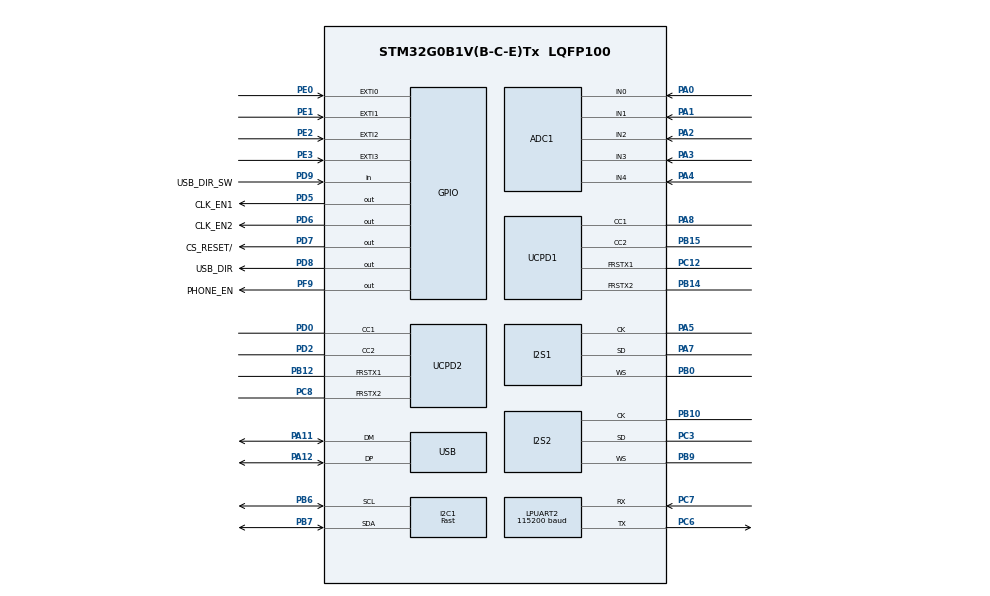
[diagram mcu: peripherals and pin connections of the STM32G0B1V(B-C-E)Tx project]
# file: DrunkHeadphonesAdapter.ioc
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ADC1.Channel-0\#ChannelRegularConversion=ADC_CHANNEL_1
ADC1.Channel-1\#ChannelRegularConversion=ADC_CHANNEL_3
ADC1.Channel-2\#ChannelRegularConversion=ADC_CHANNEL_0
ADC1.Channel-3\#ChannelRegularConversion=ADC_CHANNEL_2
ADC1.Channel-4\#ChannelRegularConversion=ADC_CHANNEL_4
ADC1.Channel-5\#ChannelRegularConversion=ADC_CHANNEL_VREFINT
ADC1.Channel-6\#ChannelRegularConversion=ADC_CHANNEL_TEMPSENSOR
ADC1.ContinuousConvMode=ENABLE
ADC1.DMAContinuousRequests=ENABLE
ADC1.EOCSelection=ADC_EOC_SEQ_CONV
ADC1.EnableAnalogWatchDog1=false
ADC1.EnableAnalogWatchDog2=false
ADC1.NbrOfConversion=7
ADC1.NbrOfConversionFlag=1
ADC1.Overrun=ADC_OVR_DATA_OVERWRITTEN
ADC1.Rank-0\#ChannelRegularConversion=1
ADC1.Rank-1\#ChannelRegularConversion=2
ADC1.Rank-2\#ChannelRegularConversion=3
ADC1.Rank-3\#ChannelRegularConversion=4
ADC1.Rank-4\#ChannelRegularConversion=5
ADC1.Rank-5\#ChannelRegularConversion=6
ADC1.Rank-6\#ChannelRegularConversion=7
ADC1.SamplingTime-0\#ChannelRegularConversion=ADC_SAMPLINGTIME_COMMON_1
ADC1.SamplingTime-1\#ChannelRegularConversion=ADC_SAMPLINGTIME_COMMON_1
ADC1.SamplingTime-2\#ChannelRegularConversion=ADC_SAMPLINGTIME_COMMON_1
ADC1.SamplingTime-3\#ChannelRegularConversion=ADC_SAMPLINGTIME_COMMON_1
ADC1.SamplingTime-4\#ChannelRegularConversion=ADC_SAMPLINGTIME_COMMON_1
ADC1.SamplingTime-5\#ChannelRegularConversion=ADC_SAMPLINGTIME_COMMON_2
ADC1.SamplingTime-6\#ChannelRegularConversion=ADC_SAMPLINGTIME_COMMON_2
ADC1.SamplingTimeCommon1=ADC_SAMPLETIME_39CYCLES_5
ADC1.SamplingTimeCommon2=ADC_SAMPLETIME_160CYCLES_5
ADC1.SelectedChannel=ADC_CHANNEL_0|ADC_CHANNEL_1|ADC_CHANNEL_2|ADC_CHANNEL_3|ADC_CHANNEL_4|ADC_CHANNEL_TEMPSENSOR|ADC_CHANNEL_VREFINT
ADC1.master=1
Dma.ADC1.4.Direction=DMA_PERIPH_TO_MEMORY
Dma.ADC1.4.EventEnable=DISABLE
Dma.ADC1.4.Instance=DMA1_Channel5
Dma.ADC1.4.MemDataAlignment=DMA_MDATAALIGN_HALFWORD
Dma.ADC1.4.MemInc=DMA_MINC_ENABLE
Dma.ADC1.4.Mode=DMA_CIRCULAR
Dma.ADC1.4.PeriphDataAlignment=DMA_PDATAALIGN_HALFWORD
Dma.ADC1.4.PeriphInc=DMA_PINC_DISABLE
Dma.ADC1.4.Polarity=HAL_DMAMUX_REQ_GEN_RISING
Dma.ADC1.4.Priority=DMA_PRIORITY_LOW
Dma.ADC1.4.RequestNumber=1
Dma.ADC1.4.SignalID=NONE
Dma.ADC1.4.SyncEnable=DISABLE
Dma.ADC1.4.SyncPolarity=HAL_DMAMUX_SYNC_NO_EVENT
Dma.ADC1.4.SyncRequestNumber=1
Dma.ADC1.4.SyncSignalID=NONE
Dma.Request0=UCPD1_RX
Dma.Request1=UCPD1_TX
Dma.Request2=UCPD2_RX
Dma.Request3=UCPD2_TX
Dma.Request4=ADC1
Dma.UCPD1_RX.0.Direction=DMA_PERIPH_TO_MEMORY
Dma.UCPD1_RX.0.EventEnable=DISABLE
Dma.UCPD1_RX.0.Instance=DMA1_Channel1
Dma.UCPD1_RX.0.MemDataAlignment=DMA_MDATAALIGN_BYTE
Dma.UCPD1_RX.0.MemInc=DMA_MINC_ENABLE
Dma.UCPD1_RX.0.Mode=DMA_NORMAL
Dma.UCPD1_RX.0.PeriphDataAlignment=DMA_PDATAALIGN_BYTE
Dma.UCPD1_RX.0.PeriphInc=DMA_PINC_DISABLE
Dma.UCPD1_RX.0.Polarity=HAL_DMAMUX_REQ_GEN_RISING
Dma.UCPD1_RX.0.Priority=DMA_PRIORITY_LOW
Dma.UCPD1_RX.0.RequestNumber=1
Dma.UCPD1_RX.0.SignalID=NONE
Dma.UCPD1_RX.0.SyncEnable=DISABLE
Dma.UCPD1_RX.0.SyncPolarity=HAL_DMAMUX_SYNC_NO_EVENT
Dma.UCPD1_RX.0.SyncRequestNumber=1
Dma.UCPD1_RX.0.SyncSignalID=NONE
Dma.UCPD1_TX.1.Direction=DMA_MEMORY_TO_PERIPH
Dma.UCPD1_TX.1.EventEnable=DISABLE
Dma.UCPD1_TX.1.Instance=DMA1_Channel2
Dma.UCPD1_TX.1.MemDataAlignment=DMA_MDATAALIGN_BYTE
Dma.UCPD1_TX.1.MemInc=DMA_MINC_ENABLE
Dma.UCPD1_TX.1.Mode=DMA_NORMAL
Dma.UCPD1_TX.1.PeriphDataAlignment=DMA_PDATAALIGN_BYTE
Dma.UCPD1_TX.1.PeriphInc=DMA_PINC_DISABLE
Dma.UCPD1_TX.1.Polarity=HAL_DMAMUX_REQ_GEN_RISING
Dma.UCPD1_TX.1.Priority=DMA_PRIORITY_LOW
Dma.UCPD1_TX.1.RequestNumber=1
Dma.UCPD1_TX.1.SignalID=NONE
Dma.UCPD1_TX.1.SyncEnable=DISABLE
Dma.UCPD1_TX.1.SyncPolarity=HAL_DMAMUX_SYNC_NO_EVENT
Dma.UCPD1_TX.1.SyncRequestNumber=1
Dma.UCPD1_TX.1.SyncSignalID=NONE
Dma.UCPD2_RX.2.Direction=DMA_PERIPH_TO_MEMORY
Dma.UCPD2_RX.2.EventEnable=DISABLE
Dma.UCPD2_RX.2.Instance=DMA1_Channel3
Dma.UCPD2_RX.2.MemDataAlignment=DMA_MDATAALIGN_BYTE
Dma.UCPD2_RX.2.MemInc=DMA_MINC_ENABLE
Dma.UCPD2_RX.2.Mode=DMA_NORMAL
Dma.UCPD2_RX.2.PeriphDataAlignment=DMA_PDATAALIGN_BYTE
Dma.UCPD2_RX.2.PeriphInc=DMA_PINC_DISABLE
Dma.UCPD2_RX.2.Polarity=HAL_DMAMUX_REQ_GEN_RISING
Dma.UCPD2_RX.2.Priority=DMA_PRIORITY_LOW
Dma.UCPD2_RX.2.RequestNumber=1
Dma.UCPD2_RX.2.SignalID=NONE
Dma.UCPD2_RX.2.SyncEnable=DISABLE
Dma.UCPD2_RX.2.SyncPolarity=HAL_DMAMUX_SYNC_NO_EVENT
Dma.UCPD2_RX.2.SyncRequestNumber=1
Dma.UCPD2_RX.2.SyncSignalID=NONE
Dma.UCPD2_TX.3.Direction=DMA_MEMORY_TO_PERIPH
Dma.UCPD2_TX.3.EventEnable=DISABLE
Dma.UCPD2_TX.3.Instance=DMA1_Channel4
Dma.UCPD2_TX.3.MemDataAlignment=DMA_MDATAALIGN_BYTE
Dma.UCPD2_TX.3.MemInc=DMA_MINC_ENABLE
Dma.UCPD2_TX.3.Mode=DMA_NORMAL
Dma.UCPD2_TX.3.PeriphDataAlignment=DMA_PDATAALIGN_BYTE
Dma.UCPD2_TX.3.PeriphInc=DMA_PINC_DISABLE
Dma.UCPD2_TX.3.Polarity=HAL_DMAMUX_REQ_GEN_RISING
Dma.UCPD2_TX.3.Priority=DMA_PRIORITY_LOW
Dma.UCPD2_TX.3.RequestNumber=1
Dma.UCPD2_TX.3.SignalID=NONE
Dma.UCPD2_TX.3.SyncEnable=DISABLE
Dma.UCPD2_TX.3.SyncPolarity=HAL_DMAMUX_SYNC_NO_EVENT
Dma.UCPD2_TX.3.SyncRequestNumber=1
Dma.UCPD2_TX.3.SyncSignalID=NONE
FREERTOS.Tasks01=defaultTask,24,128,StartDefaultTask,Default,NULL,Dynamic,NULL,NULL
FREERTOS.configTOTAL_HEAP_SIZE=32768
FREERTOS.configUSE_TICKLESS_IDLE=1
I2C1.I2C_Rise_Time=300
I2C1.I2C_Speed_Mode=I2C_Fast
I2C1.Timing=0x00600614
I2S1.AudioFreq=I2S_AUDIOFREQ_96K
I2S1.DataFormat=I2S_DATAFORMAT_32B
I2S1.ErrorAudioFreq=4.16 %
I2S1.FullDuplexMode=I2S_FULLDUPLEXMODE_DISABLE
I2S1.Instance=SPI$Index
I2S1.RealAudioFreq=100.0 KHz
I2S1.VirtualMode=I2S_MODE_SLAVE
I2S2.AudioFreq=I2S_AUDIOFREQ_96K
I2S2.DataFormat=I2S_DATAFORMAT_24B
I2S2.ErrorAudioFreq=4.16 %
I2S2.FullDuplexMode=I2S_FULLDUPLEXMODE_DISABLE
I2S2.Instance=SPI$Index
I2S2.RealAudioFreq=100.0 KHz
I2S2.VirtualMode=I2S_MODE_SLAVE
LPUART2.BaudRate=115200
LPUART2.WordLength=UART_WORDLENGTH_8B
Mcu.Family=STM32G0
Mcu.Name=STM32G0B1V(B-C-E)Tx
Mcu.Package=LQFP100
NVIC.ADC1_COMP_IRQn=true\:3\:0\:false\:false\:true\:true\:true\:true\:true
NVIC.DMA1_Ch4_7_DMA2_Ch1_5_DMAMUX1_OVR_IRQn=true\:3\:0\:false\:false\:true\:true\:false\:true\:true
NVIC.DMA1_Channel1_IRQn=true\:3\:0\:false\:false\:true\:true\:false\:true\:true
NVIC.DMA1_Channel2_3_IRQn=true\:3\:0\:false\:false\:true\:true\:false\:true\:true
NVIC.EXTI0_1_IRQn=true\:3\:0\:false\:false\:true\:true\:true\:true\:true
NVIC.EXTI2_3_IRQn=true\:3\:0\:false\:false\:true\:true\:true\:true\:true
NVIC.TIM6_DAC_LPTIM1_IRQn=true\:3\:0\:false\:false\:true\:false\:false\:true\:true
NVIC.TimeBase=TIM6_DAC_LPTIM1_IRQn
NVIC.TimeBaseIP=TIM6
NVIC.USB_UCPD1_2_IRQn=true\:3\:0\:true\:false\:true\:true\:true\:true\:true
PA0.Mode=IN0
PA0.Signal=ADC1_IN0
PA1.Mode=IN1
PA1.Signal=ADC1_IN1
PA11\ [PA9].Mode=Device
PA11\ [PA9].Signal=USB_DM
PA12\ [PA10].Mode=Device
PA12\ [PA10].Signal=USB_DP
PA13.Mode=Serial_Wire
PA13.Signal=SYS_SWDIO
PA14-BOOT0.Mode=Serial_Wire
PA14-BOOT0.Signal=SYS_SWCLK
PA2.Mode=IN2
PA2.Signal=ADC1_IN2
PA3.Mode=IN3
PA3.Signal=ADC1_IN3
PA4.Mode=IN4
PA4.Signal=ADC1_IN4
PA5.Mode=Half_Duplex_Slave
PA5.Signal=I2S1_CK
PA7.Mode=Half_Duplex_Slave
PA7.Signal=I2S1_SD
PA8.Mode=Dual_Role_AllSignals
PA8.Signal=UCPD1_CC1
PB0.Mode=Half_Duplex_Slave
PB0.Signal=I2S1_WS
PB10.Mode=Half_Duplex_Slave
PB10.Signal=I2S2_CK
PB12.Mode=FRSTX_CC2
PB12.Signal=UCPD2_FRSTX1
PB14.Mode=FRSTX_CC2
PB14.Signal=UCPD1_FRSTX2
PB15.Mode=Dual_Role_AllSignals
PB15.Signal=UCPD1_CC2
PB6.Mode=I2C
PB6.Signal=I2C1_SCL
PB7.Mode=I2C
PB7.Signal=I2C1_SDA
PB9.Mode=Half_Duplex_Slave
PB9.Signal=I2S2_WS
PC12.Mode=FRSTX_CC2
PC12.Signal=UCPD1_FRSTX1
PC3.Mode=Half_Duplex_Slave
PC3.Signal=I2S2_SD
PC6.Mode=Asynchronous
PC6.Signal=LPUART2_TX
PC7.Mode=Asynchronous
PC7.Signal=LPUART2_RX
PC8.Mode=FRSTX_CC2
PC8.Signal=UCPD2_FRSTX2
PD0.Mode=Dual_Role_AllSignals
PD0.Signal=UCPD2_CC1
PD2.Mode=Dual_Role_AllSignals
PD2.Signal=UCPD2_CC2
PD5.GPIO_Label=CLK_EN1
PD5.Signal=GPIO_Output
PD6.GPIO_Label=CLK_EN2
PD6.Signal=GPIO_Output
PD7.GPIO_Label=CS_RESET/
PD7.Signal=GPIO_Output
PD8.GPIO_Label=USB_DIR
PD8.Signal=GPIO_Output
PD9.GPIO_Label=USB_DIR_SW
PD9.Signal=GPIO_Input
PE0.GPIO_ModeDefaultEXTI=GPIO_MODE_IT_FALLING
PE0.Signal=GPXTI0
PE1.GPIO_ModeDefaultEXTI=GPIO_MODE_IT_FALLING
PE1.Signal=GPXTI1
PE2.GPIO_ModeDefaultEXTI=GPIO_MODE_IT_FALLING
PE2.Signal=GPXTI2
PE3.GPIO_ModeDefaultEXTI=GPIO_MODE_IT_FALLING
PE3.Signal=GPXTI3
PF9.GPIO_Label=PHONE_EN
PF9.Signal=GPIO_Output
ProjectManager.HeapSize=0x200
ProjectManager.StackSize=0x400
ProjectManager.TargetToolchain=Makefile
RCC.ADCFreq_Value=64000000
RCC.AHBFreq_Value=64000000
RCC.APB1CLKDivider=RCC_HCLK_DIV4
RCC.CortexFreq_Value=64000000
RCC.EXTERNAL_CLOCK_VALUE=48000
RCC.HCLKFreq_Value=64000000
RCC.HSE_VALUE=16000000
RCC.HSI48_VALUE=48000000
RCC.HSI_VALUE=16000000
RCC.LSE_VALUE=32768
RCC.SYSCLKFreq_VALUE=64000000
RCC.SYSCLKSource=RCC_SYSCLKSOURCE_PLLCLK
RCC.USBFreq_Value=48000000
RCC.VCOOutputFreq_Value=128000000
STMicroelectronics.X-CUBE-TCPP.4.2.0.tcpp0203CcBoardOoPartJjtcpp0203Jjtcpp0203=true
VP_ADC1_TempSens_Input.Mode=IN-TempSens
VP_ADC1_Vref_Input.Mode=IN-Vrefint
VP_FREERTOS_VS_CMSIS_V2.Mode=CMSIS_V2
VP_RCC_USB.Mode=CRS SYNC Source USB
VP_STMicroelectronics.X-CUBE-TCPP_VS_BoardOoPartJjtcpp0203_1.2.3_4.2.0.Mode=BoardOoPartJjtcpp0203
VP_SYS_VS_DBSignals.Mode=DisableDeadBatterySignals
VP_SYS_VS_tim6.Mode=TIM6
VP_USBPD_VS_PD3FULL.Mode=PD3_Full_Stack
VP_USBPD_VS_USBPD12.Mode=USBPD_P0P1
VP_USBPD_VS_usbpd_tim1.Mode=TIM1
board=custom

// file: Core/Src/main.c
/* USER CODE BEGIN Header */
/**
  ******************************************************************************
  * @file           : main.c
  * @brief          : Main program body
  ******************************************************************************
  * @attention
  *
  * Copyright (c) 2026 STMicroelectronics.
  * All rights reserved.
  *
  * This software is licensed under terms that can be found in the LICENSE file
  * in the root directory of this software component.
  * If no LICENSE file comes with this software, it is provided AS-IS.
  *
  ******************************************************************************
  */
/* USER CODE END Header */
#include "main.h"
#include "cmsis_os.h"
#include "usbpd.h"

/* USER CODE BEGIN Includes */
#include "app_main.h"

/* USER CODE END Includes */

PCD_HandleTypeDef hpcd_USB_DRD_FS;

/* Definitions for defaultTask */
osThreadId_t defaultTaskHandle;
const osThreadAttr_t defaultTask_attributes = {
  .name = "defaultTask",
  .priority = (osPriority_t) osPriorityNormal,
  .stack_size = 128 * 4
};

void SystemClock_Config(void);
static void MX_GPIO_Init(void);
static void MX_DMA_Init(void);
static void MX_I2S1_Init(void);
static void MX_I2S2_Init(void);
static void MX_UCPD1_Init(void);
static void MX_UCPD2_Init(void);
static void MX_I2C1_Init(void);
static void MX_ADC1_Init(void);
static void MX_LPUART2_UART_Init(void);
static void MX_USB_DRD_FS_PCD_Init(void);
void StartDefaultTask(void *argument);

int main(void)
{

  /* MCU Configuration--------------------------------------------------------*/

  /* Reset of all peripherals, Initializes the Flash interface and the Systick. */
  HAL_Init();

  /* Configure the system clock */
  SystemClock_Config();

  /* Initialize all configured peripherals */
  MX_GPIO_Init();
  MX_DMA_Init();
  MX_I2S1_Init();
  MX_I2S2_Init();
  MX_UCPD1_Init();
  MX_UCPD2_Init();
  MX_I2C1_Init();
  MX_ADC1_Init();
  MX_LPUART2_UART_Init();

  /* Init scheduler */
  osKernelInitialize();
  /* USBPD initialisation ---------------------------------*/
  MX_USBPD_Init();

  /* Create the thread(s) */
  /* creation of defaultTask */
  defaultTaskHandle = osThreadNew(StartDefaultTask, NULL, &defaultTask_attributes);

  /* Start scheduler */
  osKernelStart();

  /* We should never get here as control is now taken by the scheduler */

  /* Infinite loop */
  /* USER CODE BEGIN WHILE */
  app_main();
  while (1)
  {
    /* USER CODE END WHILE */

  }
}

void SystemClock_Config(void)
{
  LL_FLASH_SetLatency(LL_FLASH_LATENCY_2);
  while(LL_FLASH_GetLatency() != LL_FLASH_LATENCY_2)
  {
  }

  /* HSI configuration and activation */
  LL_RCC_HSI_Enable();
  while(LL_RCC_HSI_IsReady() != 1)
  {
  }

  LL_RCC_HSI48_Enable();

   /* Wait till HSI48 is ready */
  while(LL_RCC_HSI48_IsReady() != 1)
  {
  }

  /* Main PLL configuration and activation */
  LL_RCC_PLL_ConfigDomain_SYS(LL_RCC_PLLSOURCE_HSI, LL_RCC_PLLM_DIV_1, 8, LL_RCC_PLLR_DIV_2);
  LL_RCC_PLL_Enable();
  LL_RCC_PLL_EnableDomain_SYS();
  while(LL_RCC_PLL_IsReady() != 1)
  {
  }

  /* Set AHB prescaler*/
  LL_RCC_SetAHBPrescaler(LL_RCC_SYSCLK_DIV_1);

  /* Sysclk activation on the main PLL */
  LL_RCC_SetSysClkSource(LL_RCC_SYS_CLKSOURCE_PLL);
  while(LL_RCC_GetSysClkSource() != LL_RCC_SYS_CLKSOURCE_STATUS_PLL)
  {
  }

  /* Set APB1 prescaler*/
  LL_RCC_SetAPB1Prescaler(LL_RCC_APB1_DIV_4);
  /* Update CMSIS variable (which can be updated also through SystemCoreClockUpdate function) */
  LL_SetSystemCoreClock(64000000);

   /* Update the time base */
  if (HAL_InitTick (TICK_INT_PRIORITY) != HAL_OK)
  {
    Error_Handler();
  }
  LL_APB1_GRP1_EnableClock(LL_APB1_GRP1_PERIPH_CRS);
  LL_APB1_GRP1_ForceReset(LL_APB1_GRP1_PERIPH_CRS);
  LL_APB1_GRP1_ReleaseReset(LL_APB1_GRP1_PERIPH_CRS);
  LL_CRS_SetSyncDivider(LL_CRS_SYNC_DIV_1);
  LL_CRS_SetSyncPolarity(LL_CRS_SYNC_POLARITY_RISING);
  LL_CRS_SetSyncSignalSource(LL_CRS_SYNC_SOURCE_USB);
  LL_CRS_SetReloadCounter(__LL_CRS_CALC_CALCULATE_RELOADVALUE(48000000,1000));
  LL_CRS_SetFreqErrorLimit(34);
  LL_CRS_SetHSI48SmoothTrimming(32);
}

static void MX_ADC1_Init(void)
{

  LL_ADC_InitTypeDef ADC_InitStruct = {0};
  LL_ADC_REG_InitTypeDef ADC_REG_InitStruct = {0};

  LL_GPIO_InitTypeDef GPIO_InitStruct = {0};

  /* Peripheral clock enable */
  LL_APB2_GRP1_EnableClock(LL_APB2_GRP1_PERIPH_ADC);

  LL_IOP_GRP1_EnableClock(LL_IOP_GRP1_PERIPH_GPIOA);
  /**ADC1 GPIO Configuration
  PA0   ------> ADC1_IN0
  PA1   ------> ADC1_IN1
  PA2   ------> ADC1_IN2
  PA3   ------> ADC1_IN3
  PA4   ------> ADC1_IN4
  */
  GPIO_InitStruct.Pin = LL_GPIO_PIN_0;
  GPIO_InitStruct.Mode = LL_GPIO_MODE_ANALOG;
  GPIO_InitStruct.Pull = LL_GPIO_PULL_NO;
  LL_GPIO_Init(GPIOA, &GPIO_InitStruct);

  GPIO_InitStruct.Pin = LL_GPIO_PIN_1;
  GPIO_InitStruct.Mode = LL_GPIO_MODE_ANALOG;
  GPIO_InitStruct.Pull = LL_GPIO_PULL_NO;
  LL_GPIO_Init(GPIOA, &GPIO_InitStruct);

  GPIO_InitStruct.Pin = LL_GPIO_PIN_2;
  GPIO_InitStruct.Mode = LL_GPIO_MODE_ANALOG;
  GPIO_InitStruct.Pull = LL_GPIO_PULL_NO;
  LL_GPIO_Init(GPIOA, &GPIO_InitStruct);

  GPIO_InitStruct.Pin = LL_GPIO_PIN_3;
  GPIO_InitStruct.Mode = LL_GPIO_MODE_ANALOG;
  GPIO_InitStruct.Pull = LL_GPIO_PULL_NO;
  LL_GPIO_Init(GPIOA, &GPIO_InitStruct);

  GPIO_InitStruct.Pin = LL_GPIO_PIN_4;
  GPIO_InitStruct.Mode = LL_GPIO_MODE_ANALOG;
  GPIO_InitStruct.Pull = LL_GPIO_PULL_NO;
  LL_GPIO_Init(GPIOA, &GPIO_InitStruct);

  /* ADC1 DMA Init */

  /* ADC1 Init */
  LL_DMA_SetPeriphRequest(DMA1, LL_DMA_CHANNEL_5, LL_DMAMUX_REQ_ADC1);

  LL_DMA_SetDataTransferDirection(DMA1, LL_DMA_CHANNEL_5, LL_DMA_DIRECTION_PERIPH_TO_MEMORY);

  LL_DMA_SetChannelPriorityLevel(DMA1, LL_DMA_CHANNEL_5, LL_DMA_PRIORITY_LOW);

  LL_DMA_SetMode(DMA1, LL_DMA_CHANNEL_5, LL_DMA_MODE_CIRCULAR);

  LL_DMA_SetPeriphIncMode(DMA1, LL_DMA_CHANNEL_5, LL_DMA_PERIPH_NOINCREMENT);

  LL_DMA_SetMemoryIncMode(DMA1, LL_DMA_CHANNEL_5, LL_DMA_MEMORY_INCREMENT);

  LL_DMA_SetPeriphSize(DMA1, LL_DMA_CHANNEL_5, LL_DMA_PDATAALIGN_HALFWORD);

  LL_DMA_SetMemorySize(DMA1, LL_DMA_CHANNEL_5, LL_DMA_MDATAALIGN_HALFWORD);

  /* ADC1 interrupt Init */
  NVIC_SetPriority(ADC1_COMP_IRQn, 3);
  NVIC_EnableIRQ(ADC1_COMP_IRQn);

  /** Configure the global features of the ADC (Clock, Resolution, Data Alignment and number of conversion)
  */

   #define ADC_CHANNEL_CONF_RDY_TIMEOUT_MS ( 1U)
   #if (USE_TIMEOUT == 1)
   uint32_t Timeout ; /* Variable used for Timeout management */
   #endif /* USE_TIMEOUT */

  ADC_InitStruct.Clock = LL_ADC_CLOCK_SYNC_PCLK_DIV2;
  ADC_InitStruct.Resolution = LL_ADC_RESOLUTION_12B;
  ADC_InitStruct.DataAlignment = LL_ADC_DATA_ALIGN_RIGHT;
  ADC_InitStruct.LowPowerMode = LL_ADC_LP_MODE_NONE;
  LL_ADC_Init(ADC1, &ADC_InitStruct);
  LL_ADC_REG_SetSequencerConfigurable(ADC1, LL_ADC_REG_SEQ_CONFIGURABLE);

   /* Poll for ADC channel configuration ready */
   #if (USE_TIMEOUT == 1)
   Timeout = ADC_CHANNEL_CONF_RDY_TIMEOUT_MS;
   #endif /* USE_TIMEOUT */
   while (LL_ADC_IsActiveFlag_CCRDY(ADC1) == 0)
     {
   #if (USE_TIMEOUT == 1)
   /* Check Systick counter flag to decrement the time-out value */
   if (LL_SYSTICK_IsActiveCounterFlag())
     {
   if(Timeout-- == 0)
         {
   Error_Handler();
         }
     }
   #endif /* USE_TIMEOUT */
     }
   /* Clear flag ADC channel configuration ready */
   LL_ADC_ClearFlag_CCRDY(ADC1);
  ADC_REG_InitStruct.TriggerSource = LL_ADC_REG_TRIG_SOFTWARE;
  ADC_REG_InitStruct.SequencerLength = LL_ADC_REG_SEQ_SCAN_ENABLE_7RANKS;
  ADC_REG_InitStruct.ContinuousMode = LL_ADC_REG_CONV_CONTINUOUS;
  ADC_REG_InitStruct.DMATransfer = LL_ADC_REG_DMA_TRANSFER_UNLIMITED;
  ADC_REG_InitStruct.Overrun = LL_ADC_REG_OVR_DATA_OVERWRITTEN;
  LL_ADC_REG_Init(ADC1, &ADC_REG_InitStruct);
  LL_ADC_SetOverSamplingScope(ADC1, LL_ADC_OVS_DISABLE);
  LL_ADC_SetTriggerFrequencyMode(ADC1, LL_ADC_CLOCK_FREQ_MODE_HIGH);
  LL_ADC_SetCommonPathInternalCh(__LL_ADC_COMMON_INSTANCE(ADC1), LL_ADC_PATH_INTERNAL_VREFINT|LL_ADC_PATH_INTERNAL_TEMPSENSOR);
  LL_ADC_SetSamplingTimeCommonChannels(ADC1, LL_ADC_SAMPLINGTIME_COMMON_1, LL_ADC_SAMPLINGTIME_39CYCLES_5);
  LL_ADC_SetSamplingTimeCommonChannels(ADC1, LL_ADC_SAMPLINGTIME_COMMON_2, LL_ADC_SAMPLINGTIME_160CYCLES_5);
  LL_ADC_DisableIT_EOC(ADC1);
  LL_ADC_DisableIT_EOS(ADC1);

   /* Enable ADC internal voltage regulator */
   LL_ADC_EnableInternalRegulator(ADC1);
   /* Delay for ADC internal voltage regulator stabilization. */
   /* Compute number of CPU cycles to wait for, from delay in us. */
   /* Note: Variable divided by 2 to compensate partially */
   /* CPU processing cycles (depends on compilation optimization). */
   /* Note: If system core clock frequency is below 200kHz, wait time */
   /* is only a few CPU processing cycles. */
   __IO uint32_t wait_loop_index;
   wait_loop_index = ((LL_ADC_DELAY_INTERNAL_REGUL_STAB_US * (SystemCoreClock / (100000 * 2))) / 10);
   while(wait_loop_index != 0)
     {
   wait_loop_index--;
     }

  /** Configure Regular Channel
  */
  LL_ADC_REG_SetSequencerRanks(ADC1, LL_ADC_REG_RANK_1, LL_ADC_CHANNEL_1);

   /* Poll for ADC channel configuration ready */
   #if (USE_TIMEOUT == 1)
   Timeout = ADC_CHANNEL_CONF_RDY_TIMEOUT_MS;
   #endif /* USE_TIMEOUT */
   while (LL_ADC_IsActiveFlag_CCRDY(ADC1) == 0)
     {
   #if (USE_TIMEOUT == 1)
   /* Check Systick counter flag to decrement the time-out value */
   if (LL_SYSTICK_IsActiveCounterFlag())
     {
   if(Timeout-- == 0)
         {
   Error_Handler();
         }
     }
   #endif /* USE_TIMEOUT */
     }
   /* Clear flag ADC channel configuration ready */
   LL_ADC_ClearFlag_CCRDY(ADC1);
  LL_ADC_SetChannelSamplingTime(ADC1, LL_ADC_CHANNEL_1, LL_ADC_SAMPLINGTIME_COMMON_1);

  /** Configure Regular Channel
  */
  LL_ADC_REG_SetSequencerRanks(ADC1, LL_ADC_REG_RANK_2, LL_ADC_CHANNEL_3);

   /* Poll for ADC channel configuration ready */
   #if (USE_TIMEOUT == 1)
   Timeout = ADC_CHANNEL_CONF_RDY_TIMEOUT_MS;
   #endif /* USE_TIMEOUT */
   while (LL_ADC_IsActiveFlag_CCRDY(ADC1) == 0)
     {
   #if (USE_TIMEOUT == 1)
   /* Check Systick counter flag to decrement the time-out value */
   if (LL_SYSTICK_IsActiveCounterFlag())
     {
   if(Timeout-- == 0)
         {
   Error_Handler();
         }
     }
   #endif /* USE_TIMEOUT */
     }
   /* Clear flag ADC channel configuration ready */
   LL_ADC_ClearFlag_CCRDY(ADC1);
  LL_ADC_SetChannelSamplingTime(ADC1, LL_ADC_CHANNEL_3, LL_ADC_SAMPLINGTIME_COMMON_1);

  /** Configure Regular Channel
  */
  LL_ADC_REG_SetSequencerRanks(ADC1, LL_ADC_REG_RANK_3, LL_ADC_CHANNEL_0);
  LL_ADC_SetChannelSamplingTime(ADC1, LL_ADC_CHANNEL_0, LL_ADC_SAMPLINGTIME_COMMON_1);

  /** Configure Regular Channel
  */
  LL_ADC_REG_SetSequencerRanks(ADC1, LL_ADC_REG_RANK_4, LL_ADC_CHANNEL_2);

   /* Poll for ADC channel configuration ready */
   #if (USE_TIMEOUT == 1)
   Timeout = ADC_CHANNEL_CONF_RDY_TIMEOUT_MS;
   #endif /* USE_TIMEOUT */
   while (LL_ADC_IsActiveFlag_CCRDY(ADC1) == 0)
     {
   #if (USE_TIMEOUT == 1)
   /* Check Systick counter flag to decrement the time-out value */
   if (LL_SYSTICK_IsActiveCounterFlag())
     {
   if(Timeout-- == 0)
         {
   Error_Handler();
         }
     }
   #endif /* USE_TIMEOUT */
     }
   /* Clear flag ADC channel configuration ready */
   LL_ADC_ClearFlag_CCRDY(ADC1);
  LL_ADC_SetChannelSamplingTime(ADC1, LL_ADC_CHANNEL_2, LL_ADC_SAMPLINGTIME_COMMON_1);

  /** Configure Regular Channel
  */
  LL_ADC_REG_SetSequencerRanks(ADC1, LL_ADC_REG_RANK_5, LL_ADC_CHANNEL_4);

   /* Poll for ADC channel configuration ready */
   #if (USE_TIMEOUT == 1)
   Timeout = ADC_CHANNEL_CONF_RDY_TIMEOUT_MS;
   #endif /* USE_TIMEOUT */
   while (LL_ADC_IsActiveFlag_CCRDY(ADC1) == 0)
     {
   #if (USE_TIMEOUT == 1)
   /* Check Systick counter flag to decrement the time-out value */
   if (LL_SYSTICK_IsActiveCounterFlag())
     {
   if(Timeout-- == 0)
         {
   Error_Handler();
         }
     }
   #endif /* USE_TIMEOUT */
     }
   /* Clear flag ADC channel configuration ready */
   LL_ADC_ClearFlag_CCRDY(ADC1);
  LL_ADC_SetChannelSamplingTime(ADC1, LL_ADC_CHANNEL_4, LL_ADC_SAMPLINGTIME_COMMON_1);

  /** Configure Regular Channel
  */
  LL_ADC_REG_SetSequencerRanks(ADC1, LL_ADC_REG_RANK_6, LL_ADC_CHANNEL_VREFINT);

   /* Poll for ADC channel configuration ready */
   #if (USE_TIMEOUT == 1)
   Timeout = ADC_CHANNEL_CONF_RDY_TIMEOUT_MS;
   #endif /* USE_TIMEOUT */
   while (LL_ADC_IsActiveFlag_CCRDY(ADC1) == 0)
     {
   #if (USE_TIMEOUT == 1)
   /* Check Systick counter flag to decrement the time-out value */
   if (LL_SYSTICK_IsActiveCounterFlag())
     {
   if(Timeout-- == 0)
         {
   Error_Handler();
         }
     }
   #endif /* USE_TIMEOUT */
     }
   /* Clear flag ADC channel configuration ready */
   LL_ADC_ClearFlag_CCRDY(ADC1);
  LL_ADC_SetChannelSamplingTime(ADC1, LL_ADC_CHANNEL_VREFINT, LL_ADC_SAMPLINGTIME_COMMON_2);

  /** Configure Regular Channel
  */
  LL_ADC_REG_SetSequencerRanks(ADC1, LL_ADC_REG_RANK_7, LL_ADC_CHANNEL_TEMPSENSOR);

   /* Poll for ADC channel configuration ready */
   #if (USE_TIMEOUT == 1)
   Timeout = ADC_CHANNEL_CONF_RDY_TIMEOUT_MS;
   #endif /* USE_TIMEOUT */
   while (LL_ADC_IsActiveFlag_CCRDY(ADC1) == 0)
     {
   #if (USE_TIMEOUT == 1)
   /* Check Systick counter flag to decrement the time-out value */
   if (LL_SYSTICK_IsActiveCounterFlag())
     {
   if(Timeout-- == 0)
         {
   Error_Handler();
         }
     }
   #endif /* USE_TIMEOUT */
     }
   /* Clear flag ADC channel configuration ready */
   LL_ADC_ClearFlag_CCRDY(ADC1);
  LL_ADC_SetChannelSamplingTime(ADC1, LL_ADC_CHANNEL_TEMPSENSOR, LL_ADC_SAMPLINGTIME_COMMON_2);

}

static void MX_I2C1_Init(void)
{

  LL_I2C_InitTypeDef I2C_InitStruct = {0};

  LL_GPIO_InitTypeDef GPIO_InitStruct = {0};

  LL_RCC_SetI2CClockSource(LL_RCC_I2C1_CLKSOURCE_PCLK1);

  LL_IOP_GRP1_EnableClock(LL_IOP_GRP1_PERIPH_GPIOB);
  /**I2C1 GPIO Configuration
  PB6   ------> I2C1_SCL
  PB7   ------> I2C1_SDA
  */
  GPIO_InitStruct.Pin = LL_GPIO_PIN_6;
  GPIO_InitStruct.Mode = LL_GPIO_MODE_ALTERNATE;
  GPIO_InitStruct.Speed = LL_GPIO_SPEED_FREQ_LOW;
  GPIO_InitStruct.OutputType = LL_GPIO_OUTPUT_OPENDRAIN;
  GPIO_InitStruct.Pull = LL_GPIO_PULL_NO;
  GPIO_InitStruct.Alternate = LL_GPIO_AF_6;
  LL_GPIO_Init(GPIOB, &GPIO_InitStruct);

  GPIO_InitStruct.Pin = LL_GPIO_PIN_7;
  GPIO_InitStruct.Mode = LL_GPIO_MODE_ALTERNATE;
  GPIO_InitStruct.Speed = LL_GPIO_SPEED_FREQ_LOW;
  GPIO_InitStruct.OutputType = LL_GPIO_OUTPUT_OPENDRAIN;
  GPIO_InitStruct.Pull = LL_GPIO_PULL_NO;
  GPIO_InitStruct.Alternate = LL_GPIO_AF_6;
  LL_GPIO_Init(GPIOB, &GPIO_InitStruct);

  /* Peripheral clock enable */
  LL_APB1_GRP1_EnableClock(LL_APB1_GRP1_PERIPH_I2C1);

  /** I2C Initialization
  */
  I2C_InitStruct.PeripheralMode = LL_I2C_MODE_I2C;
  I2C_InitStruct.Timing = 0x00600614;
  I2C_InitStruct.AnalogFilter = LL_I2C_ANALOGFILTER_ENABLE;
  I2C_InitStruct.DigitalFilter = 0;
  I2C_InitStruct.OwnAddress1 = 0;
  I2C_InitStruct.TypeAcknowledge = LL_I2C_ACK;
  I2C_InitStruct.OwnAddrSize = LL_I2C_OWNADDRESS1_7BIT;
  LL_I2C_Init(I2C1, &I2C_InitStruct);
  LL_I2C_EnableAutoEndMode(I2C1);
  LL_I2C_SetOwnAddress2(I2C1, 0, LL_I2C_OWNADDRESS2_NOMASK);
  LL_I2C_DisableOwnAddress2(I2C1);
  LL_I2C_DisableGeneralCall(I2C1);
  LL_I2C_EnableClockStretching(I2C1);

}

static void MX_I2S1_Init(void)
{

  LL_I2S_InitTypeDef I2S_InitStruct = {0};

  LL_GPIO_InitTypeDef GPIO_InitStruct = {0};

  LL_RCC_SetI2SClockSource(LL_RCC_I2S1_CLKSOURCE_SYSCLK);

  /* Peripheral clock enable */
  LL_APB2_GRP1_EnableClock(LL_APB2_GRP1_PERIPH_SPI1);

  LL_IOP_GRP1_EnableClock(LL_IOP_GRP1_PERIPH_GPIOA);
  LL_IOP_GRP1_EnableClock(LL_IOP_GRP1_PERIPH_GPIOB);
  /**I2S1 GPIO Configuration
  PA5   ------> I2S1_CK
  PA7   ------> I2S1_SD
  PB0   ------> I2S1_WS
  */
  GPIO_InitStruct.Pin = LL_GPIO_PIN_5;
  GPIO_InitStruct.Mode = LL_GPIO_MODE_ALTERNATE;
  GPIO_InitStruct.Speed = LL_GPIO_SPEED_FREQ_LOW;
  GPIO_InitStruct.OutputType = LL_GPIO_OUTPUT_PUSHPULL;
  GPIO_InitStruct.Pull = LL_GPIO_PULL_NO;
  GPIO_InitStruct.Alternate = LL_GPIO_AF_0;
  LL_GPIO_Init(GPIOA, &GPIO_InitStruct);

  GPIO_InitStruct.Pin = LL_GPIO_PIN_7;
  GPIO_InitStruct.Mode = LL_GPIO_MODE_ALTERNATE;
  GPIO_InitStruct.Speed = LL_GPIO_SPEED_FREQ_LOW;
  GPIO_InitStruct.OutputType = LL_GPIO_OUTPUT_PUSHPULL;
  GPIO_InitStruct.Pull = LL_GPIO_PULL_NO;
  GPIO_InitStruct.Alternate = LL_GPIO_AF_0;
  LL_GPIO_Init(GPIOA, &GPIO_InitStruct);

  GPIO_InitStruct.Pin = LL_GPIO_PIN_0;
  GPIO_InitStruct.Mode = LL_GPIO_MODE_ALTERNATE;
  GPIO_InitStruct.Speed = LL_GPIO_SPEED_FREQ_LOW;
  GPIO_InitStruct.OutputType = LL_GPIO_OUTPUT_PUSHPULL;
  GPIO_InitStruct.Pull = LL_GPIO_PULL_NO;
  GPIO_InitStruct.Alternate = LL_GPIO_AF_0;
  LL_GPIO_Init(GPIOB, &GPIO_InitStruct);

  I2S_InitStruct.Mode = LL_I2S_MODE_SLAVE_TX;
  I2S_InitStruct.Standard = LL_I2S_STANDARD_PHILIPS;
  I2S_InitStruct.DataFormat = LL_I2S_DATAFORMAT_32B;
  I2S_InitStruct.MCLKOutput = LL_I2S_MCLK_OUTPUT_DISABLE;
  I2S_InitStruct.AudioFreq = LL_I2S_AUDIOFREQ_96K;
  I2S_InitStruct.ClockPolarity = LL_I2S_POLARITY_LOW;
  LL_I2S_Init(SPI1, &I2S_InitStruct);

}

static void MX_I2S2_Init(void)
{

  LL_I2S_InitTypeDef I2S_InitStruct = {0};

  LL_GPIO_InitTypeDef GPIO_InitStruct = {0};

  LL_RCC_SetI2SClockSource(LL_RCC_I2S2_CLKSOURCE_SYSCLK);

  /* Peripheral clock enable */
  LL_APB1_GRP1_EnableClock(LL_APB1_GRP1_PERIPH_SPI2);

  LL_IOP_GRP1_EnableClock(LL_IOP_GRP1_PERIPH_GPIOB);
  LL_IOP_GRP1_EnableClock(LL_IOP_GRP1_PERIPH_GPIOC);
  /**I2S2 GPIO Configuration
  PB9   ------> I2S2_WS
  PC3   ------> I2S2_SD
  PB10   ------> I2S2_CK
  */
  GPIO_InitStruct.Pin = LL_GPIO_PIN_9;
  GPIO_InitStruct.Mode = LL_GPIO_MODE_ALTERNATE;
  GPIO_InitStruct.Speed = LL_GPIO_SPEED_FREQ_LOW;
  GPIO_InitStruct.OutputType = LL_GPIO_OUTPUT_PUSHPULL;
  GPIO_InitStruct.Pull = LL_GPIO_PULL_NO;
  GPIO_InitStruct.Alternate = LL_GPIO_AF_5;
  LL_GPIO_Init(GPIOB, &GPIO_InitStruct);

  GPIO_InitStruct.Pin = LL_GPIO_PIN_3;
  GPIO_InitStruct.Mode = LL_GPIO_MODE_ALTERNATE;
  GPIO_InitStruct.Speed = LL_GPIO_SPEED_FREQ_LOW;
  GPIO_InitStruct.OutputType = LL_GPIO_OUTPUT_PUSHPULL;
  GPIO_InitStruct.Pull = LL_GPIO_PULL_NO;
  GPIO_InitStruct.Alternate = LL_GPIO_AF_1;
  LL_GPIO_Init(GPIOC, &GPIO_InitStruct);

  GPIO_InitStruct.Pin = LL_GPIO_PIN_10;
  GPIO_InitStruct.Mode = LL_GPIO_MODE_ALTERNATE;
  GPIO_InitStruct.Speed = LL_GPIO_SPEED_FREQ_LOW;
  GPIO_InitStruct.OutputType = LL_GPIO_OUTPUT_PUSHPULL;
  GPIO_InitStruct.Pull = LL_GPIO_PULL_NO;
  GPIO_InitStruct.Alternate = LL_GPIO_AF_5;
  LL_GPIO_Init(GPIOB, &GPIO_InitStruct);

  I2S_InitStruct.Mode = LL_I2S_MODE_SLAVE_TX;
  I2S_InitStruct.Standard = LL_I2S_STANDARD_PHILIPS;
  I2S_InitStruct.DataFormat = LL_I2S_DATAFORMAT_24B;
  I2S_InitStruct.MCLKOutput = LL_I2S_MCLK_OUTPUT_DISABLE;
  I2S_InitStruct.AudioFreq = LL_I2S_AUDIOFREQ_96K;
  I2S_InitStruct.ClockPolarity = LL_I2S_POLARITY_LOW;
  LL_I2S_Init(SPI2, &I2S_InitStruct);

}

static void MX_LPUART2_UART_Init(void)
{

  LL_LPUART_InitTypeDef LPUART_InitStruct = {0};

  LL_GPIO_InitTypeDef GPIO_InitStruct = {0};

  LL_RCC_SetLPUARTClockSource(LL_RCC_LPUART2_CLKSOURCE_PCLK1);

  /* Peripheral clock enable */
  LL_APB1_GRP1_EnableClock(LL_APB1_GRP1_PERIPH_LPUART2);

  LL_IOP_GRP1_EnableClock(LL_IOP_GRP1_PERIPH_GPIOC);
  /**LPUART2 GPIO Configuration
  PC6   ------> LPUART2_TX
  PC7   ------> LPUART2_RX
  */
  GPIO_InitStruct.Pin = LL_GPIO_PIN_6;
  GPIO_InitStruct.Mode = LL_GPIO_MODE_ALTERNATE;
  GPIO_InitStruct.Speed = LL_GPIO_SPEED_FREQ_LOW;
  GPIO_InitStruct.OutputType = LL_GPIO_OUTPUT_PUSHPULL;
  GPIO_InitStruct.Pull = LL_GPIO_PULL_NO;
  GPIO_InitStruct.Alternate = LL_GPIO_AF_3;
  LL_GPIO_Init(GPIOC, &GPIO_InitStruct);

  GPIO_InitStruct.Pin = LL_GPIO_PIN_7;
  GPIO_InitStruct.Mode = LL_GPIO_MODE_ALTERNATE;
  GPIO_InitStruct.Speed = LL_GPIO_SPEED_FREQ_LOW;
  GPIO_InitStruct.OutputType = LL_GPIO_OUTPUT_PUSHPULL;
  GPIO_InitStruct.Pull = LL_GPIO_PULL_NO;
  GPIO_InitStruct.Alternate = LL_GPIO_AF_3;
  LL_GPIO_Init(GPIOC, &GPIO_InitStruct);

  LPUART_InitStruct.PrescalerValue = LL_LPUART_PRESCALER_DIV1;
  LPUART_InitStruct.BaudRate = 115200;
  LPUART_InitStruct.DataWidth = LL_LPUART_DATAWIDTH_8B;
  LPUART_InitStruct.StopBits = LL_LPUART_STOPBITS_1;
  LPUART_InitStruct.Parity = LL_LPUART_PARITY_NONE;
  LPUART_InitStruct.TransferDirection = LL_LPUART_DIRECTION_TX_RX;
  LPUART_InitStruct.HardwareFlowControl = LL_LPUART_HWCONTROL_NONE;
  LL_LPUART_Init(LPUART2, &LPUART_InitStruct);
  LL_LPUART_SetTXFIFOThreshold(LPUART2, LL_LPUART_FIFOTHRESHOLD_1_8);
  LL_LPUART_SetRXFIFOThreshold(LPUART2, LL_LPUART_FIFOTHRESHOLD_1_8);
  LL_LPUART_DisableFIFO(LPUART2);

  LL_LPUART_Enable(LPUART2);

  /* Polling LPUART2 initialisation */
  while((!(LL_LPUART_IsActiveFlag_TEACK(LPUART2))) || (!(LL_LPUART_IsActiveFlag_REACK(LPUART2))))
  {
  }

}

static void MX_UCPD1_Init(void)
{

  LL_GPIO_InitTypeDef GPIO_InitStruct = {0};

  /* Peripheral clock enable */
  LL_APB1_GRP1_EnableClock(LL_APB1_GRP1_PERIPH_UCPD1);

  LL_IOP_GRP1_EnableClock(LL_IOP_GRP1_PERIPH_GPIOB);
  LL_IOP_GRP1_EnableClock(LL_IOP_GRP1_PERIPH_GPIOA);
  /**UCPD1 GPIO Configuration
  PB15   ------> UCPD1_CC2
  PA8   ------> UCPD1_CC1
  */
  GPIO_InitStruct.Pin = LL_GPIO_PIN_15;
  GPIO_InitStruct.Mode = LL_GPIO_MODE_ANALOG;
  GPIO_InitStruct.Pull = LL_GPIO_PULL_NO;
  LL_GPIO_Init(GPIOB, &GPIO_InitStruct);

  GPIO_InitStruct.Pin = LL_GPIO_PIN_8;
  GPIO_InitStruct.Mode = LL_GPIO_MODE_ANALOG;
  GPIO_InitStruct.Pull = LL_GPIO_PULL_NO;
  LL_GPIO_Init(GPIOA, &GPIO_InitStruct);

  /* UCPD1 DMA Init */

  /* UCPD1_RX Init */
  LL_DMA_SetPeriphRequest(DMA1, LL_DMA_CHANNEL_1, LL_DMAMUX_REQ_UCPD1_RX);

  LL_DMA_SetDataTransferDirection(DMA1, LL_DMA_CHANNEL_1, LL_DMA_DIRECTION_PERIPH_TO_MEMORY);

  LL_DMA_SetChannelPriorityLevel(DMA1, LL_DMA_CHANNEL_1, LL_DMA_PRIORITY_LOW);

  LL_DMA_SetMode(DMA1, LL_DMA_CHANNEL_1, LL_DMA_MODE_NORMAL);

  LL_DMA_SetPeriphIncMode(DMA1, LL_DMA_CHANNEL_1, LL_DMA_PERIPH_NOINCREMENT);

  LL_DMA_SetMemoryIncMode(DMA1, LL_DMA_CHANNEL_1, LL_DMA_MEMORY_INCREMENT);

  LL_DMA_SetPeriphSize(DMA1, LL_DMA_CHANNEL_1, LL_DMA_PDATAALIGN_BYTE);

  LL_DMA_SetMemorySize(DMA1, LL_DMA_CHANNEL_1, LL_DMA_MDATAALIGN_BYTE);

  /* UCPD1_TX Init */
  LL_DMA_SetPeriphRequest(DMA1, LL_DMA_CHANNEL_2, LL_DMAMUX_REQ_UCPD1_TX);

  LL_DMA_SetDataTransferDirection(DMA1, LL_DMA_CHANNEL_2, LL_DMA_DIRECTION_MEMORY_TO_PERIPH);

  LL_DMA_SetChannelPriorityLevel(DMA1, LL_DMA_CHANNEL_2, LL_DMA_PRIORITY_LOW);

  LL_DMA_SetMode(DMA1, LL_DMA_CHANNEL_2, LL_DMA_MODE_NORMAL);

  LL_DMA_SetPeriphIncMode(DMA1, LL_DMA_CHANNEL_2, LL_DMA_PERIPH_NOINCREMENT);

  LL_DMA_SetMemoryIncMode(DMA1, LL_DMA_CHANNEL_2, LL_DMA_MEMORY_INCREMENT);

  LL_DMA_SetPeriphSize(DMA1, LL_DMA_CHANNEL_2, LL_DMA_PDATAALIGN_BYTE);

  LL_DMA_SetMemorySize(DMA1, LL_DMA_CHANNEL_2, LL_DMA_MDATAALIGN_BYTE);

  /* UCPD1 interrupt Init */
  NVIC_SetPriority(USB_UCPD1_2_IRQn, 3);
  NVIC_EnableIRQ(USB_UCPD1_2_IRQn);

}

static void MX_UCPD2_Init(void)
{

  LL_GPIO_InitTypeDef GPIO_InitStruct = {0};

  /* Peripheral clock enable */
  LL_APB1_GRP1_EnableClock(LL_APB1_GRP1_PERIPH_UCPD2);

  LL_IOP_GRP1_EnableClock(LL_IOP_GRP1_PERIPH_GPIOD);
  /**UCPD2 GPIO Configuration
  PD0   ------> UCPD2_CC1
  PD2   ------> UCPD2_CC2
  */
  GPIO_InitStruct.Pin = LL_GPIO_PIN_0;
  GPIO_InitStruct.Mode = LL_GPIO_MODE_ANALOG;
  GPIO_InitStruct.Pull = LL_GPIO_PULL_NO;
  LL_GPIO_Init(GPIOD, &GPIO_InitStruct);

  GPIO_InitStruct.Pin = LL_GPIO_PIN_2;
  GPIO_InitStruct.Mode = LL_GPIO_MODE_ANALOG;
  GPIO_InitStruct.Pull = LL_GPIO_PULL_NO;
  LL_GPIO_Init(GPIOD, &GPIO_InitStruct);

  /* UCPD2 DMA Init */

  /* UCPD2_RX Init */
  LL_DMA_SetPeriphRequest(DMA1, LL_DMA_CHANNEL_3, LL_DMAMUX_REQ_UCPD2_RX);

  LL_DMA_SetDataTransferDirection(DMA1, LL_DMA_CHANNEL_3, LL_DMA_DIRECTION_PERIPH_TO_MEMORY);

  LL_DMA_SetChannelPriorityLevel(DMA1, LL_DMA_CHANNEL_3, LL_DMA_PRIORITY_LOW);

  LL_DMA_SetMode(DMA1, LL_DMA_CHANNEL_3, LL_DMA_MODE_NORMAL);

  LL_DMA_SetPeriphIncMode(DMA1, LL_DMA_CHANNEL_3, LL_DMA_PERIPH_NOINCREMENT);

  LL_DMA_SetMemoryIncMode(DMA1, LL_DMA_CHANNEL_3, LL_DMA_MEMORY_INCREMENT);

  LL_DMA_SetPeriphSize(DMA1, LL_DMA_CHANNEL_3, LL_DMA_PDATAALIGN_BYTE);

  LL_DMA_SetMemorySize(DMA1, LL_DMA_CHANNEL_3, LL_DMA_MDATAALIGN_BYTE);

  /* UCPD2_TX Init */
  LL_DMA_SetPeriphRequest(DMA1, LL_DMA_CHANNEL_4, LL_DMAMUX_REQ_UCPD2_TX);

  LL_DMA_SetDataTransferDirection(DMA1, LL_DMA_CHANNEL_4, LL_DMA_DIRECTION_MEMORY_TO_PERIPH);

  LL_DMA_SetChannelPriorityLevel(DMA1, LL_DMA_CHANNEL_4, LL_DMA_PRIORITY_LOW);

  LL_DMA_SetMode(DMA1, LL_DMA_CHANNEL_4, LL_DMA_MODE_NORMAL);

  LL_DMA_SetPeriphIncMode(DMA1, LL_DMA_CHANNEL_4, LL_DMA_PERIPH_NOINCREMENT);

  LL_DMA_SetMemoryIncMode(DMA1, LL_DMA_CHANNEL_4, LL_DMA_MEMORY_INCREMENT);

  LL_DMA_SetPeriphSize(DMA1, LL_DMA_CHANNEL_4, LL_DMA_PDATAALIGN_BYTE);

  LL_DMA_SetMemorySize(DMA1, LL_DMA_CHANNEL_4, LL_DMA_MDATAALIGN_BYTE);

  /* UCPD2 interrupt Init */
  NVIC_SetPriority(USB_UCPD1_2_IRQn, 3);
  NVIC_EnableIRQ(USB_UCPD1_2_IRQn);

}

static void MX_USB_DRD_FS_PCD_Init(void)
{

  hpcd_USB_DRD_FS.Instance = USB_DRD_FS;
  hpcd_USB_DRD_FS.Init.dev_endpoints = 8;
  hpcd_USB_DRD_FS.Init.Host_channels = 8;
  hpcd_USB_DRD_FS.Init.speed = PCD_SPEED_FULL;
  hpcd_USB_DRD_FS.Init.phy_itface = PCD_PHY_EMBEDDED;
  hpcd_USB_DRD_FS.Init.Sof_enable = DISABLE;
  hpcd_USB_DRD_FS.Init.low_power_enable = DISABLE;
  hpcd_USB_DRD_FS.Init.lpm_enable = DISABLE;
  hpcd_USB_DRD_FS.Init.battery_charging_enable = DISABLE;
  hpcd_USB_DRD_FS.Init.vbus_sensing_enable = DISABLE;
  hpcd_USB_DRD_FS.Init.bulk_doublebuffer_enable = DISABLE;
  hpcd_USB_DRD_FS.Init.iso_singlebuffer_enable = DISABLE;
  if (HAL_PCD_Init(&hpcd_USB_DRD_FS) != HAL_OK)
  {
    Error_Handler();
  }

}

static void MX_DMA_Init(void)
{

  /* Init with LL driver */
  /* DMA controller clock enable */
  LL_AHB1_GRP1_EnableClock(LL_AHB1_GRP1_PERIPH_DMA1);

  /* DMA interrupt init */
  /* DMA1_Channel1_IRQn interrupt configuration */
  NVIC_SetPriority(DMA1_Channel1_IRQn, 3);
  NVIC_EnableIRQ(DMA1_Channel1_IRQn);
  /* DMA1_Channel2_3_IRQn interrupt configuration */
  NVIC_SetPriority(DMA1_Channel2_3_IRQn, 3);
  NVIC_EnableIRQ(DMA1_Channel2_3_IRQn);
  /* DMA1_Ch4_7_DMA2_Ch1_5_DMAMUX1_OVR_IRQn interrupt configuration */
  NVIC_SetPriority(DMA1_Ch4_7_DMA2_Ch1_5_DMAMUX1_OVR_IRQn, 3);
  NVIC_EnableIRQ(DMA1_Ch4_7_DMA2_Ch1_5_DMAMUX1_OVR_IRQn);

}

static void MX_GPIO_Init(void)
{
  LL_EXTI_InitTypeDef EXTI_InitStruct = {0};
  LL_GPIO_InitTypeDef GPIO_InitStruct = {0};

  /* GPIO Ports Clock Enable */
  LL_IOP_GRP1_EnableClock(LL_IOP_GRP1_PERIPH_GPIOB);
  LL_IOP_GRP1_EnableClock(LL_IOP_GRP1_PERIPH_GPIOC);
  LL_IOP_GRP1_EnableClock(LL_IOP_GRP1_PERIPH_GPIOA);
  LL_IOP_GRP1_EnableClock(LL_IOP_GRP1_PERIPH_GPIOD);
  LL_IOP_GRP1_EnableClock(LL_IOP_GRP1_PERIPH_GPIOF);
  LL_IOP_GRP1_EnableClock(LL_IOP_GRP1_PERIPH_GPIOE);

  /**/
  LL_GPIO_ResetOutputPin(USB_DIR_GPIO_Port, USB_DIR_Pin);

  /**/
  LL_GPIO_ResetOutputPin(CLK_EN1_GPIO_Port, CLK_EN1_Pin);

  /**/
  LL_GPIO_ResetOutputPin(CLK_EN2_GPIO_Port, CLK_EN2_Pin);

  /**/
  LL_GPIO_ResetOutputPin(CS_RESET__GPIO_Port, CS_RESET__Pin);

  /**/
  LL_GPIO_ResetOutputPin(PHONE_EN_GPIO_Port, PHONE_EN_Pin);

  /**/
  GPIO_InitStruct.Pin = USB_DIR_Pin;
  GPIO_InitStruct.Mode = LL_GPIO_MODE_OUTPUT;
  GPIO_InitStruct.Speed = LL_GPIO_SPEED_FREQ_LOW;
  GPIO_InitStruct.OutputType = LL_GPIO_OUTPUT_PUSHPULL;
  GPIO_InitStruct.Pull = LL_GPIO_PULL_NO;
  LL_GPIO_Init(USB_DIR_GPIO_Port, &GPIO_InitStruct);

  /**/
  GPIO_InitStruct.Pin = USB_DIR_SW_Pin;
  GPIO_InitStruct.Mode = LL_GPIO_MODE_INPUT;
  GPIO_InitStruct.Pull = LL_GPIO_PULL_NO;
  LL_GPIO_Init(USB_DIR_SW_GPIO_Port, &GPIO_InitStruct);

  /**/
  GPIO_InitStruct.Pin = CLK_EN1_Pin;
  GPIO_InitStruct.Mode = LL_GPIO_MODE_OUTPUT;
  GPIO_InitStruct.Speed = LL_GPIO_SPEED_FREQ_LOW;
  GPIO_InitStruct.OutputType = LL_GPIO_OUTPUT_PUSHPULL;
  GPIO_InitStruct.Pull = LL_GPIO_PULL_NO;
  LL_GPIO_Init(CLK_EN1_GPIO_Port, &GPIO_InitStruct);

  /**/
  GPIO_InitStruct.Pin = CLK_EN2_Pin;
  GPIO_InitStruct.Mode = LL_GPIO_MODE_OUTPUT;
  GPIO_InitStruct.Speed = LL_GPIO_SPEED_FREQ_LOW;
  GPIO_InitStruct.OutputType = LL_GPIO_OUTPUT_PUSHPULL;
  GPIO_InitStruct.Pull = LL_GPIO_PULL_NO;
  LL_GPIO_Init(CLK_EN2_GPIO_Port, &GPIO_InitStruct);

  /**/
  GPIO_InitStruct.Pin = CS_RESET__Pin;
  GPIO_InitStruct.Mode = LL_GPIO_MODE_OUTPUT;
  GPIO_InitStruct.Speed = LL_GPIO_SPEED_FREQ_LOW;
  GPIO_InitStruct.OutputType = LL_GPIO_OUTPUT_PUSHPULL;
  GPIO_InitStruct.Pull = LL_GPIO_PULL_NO;
  LL_GPIO_Init(CS_RESET__GPIO_Port, &GPIO_InitStruct);

  /**/
  GPIO_InitStruct.Pin = PHONE_EN_Pin;
  GPIO_InitStruct.Mode = LL_GPIO_MODE_OUTPUT;
  GPIO_InitStruct.Speed = LL_GPIO_SPEED_FREQ_LOW;
  GPIO_InitStruct.OutputType = LL_GPIO_OUTPUT_PUSHPULL;
  GPIO_InitStruct.Pull = LL_GPIO_PULL_NO;
  LL_GPIO_Init(PHONE_EN_GPIO_Port, &GPIO_InitStruct);

  /**/
  LL_EXTI_SetEXTISource(LL_EXTI_CONFIG_PORTE, LL_EXTI_CONFIG_LINE0);

  /**/
  LL_EXTI_SetEXTISource(LL_EXTI_CONFIG_PORTE, LL_EXTI_CONFIG_LINE1);

  /**/
  LL_EXTI_SetEXTISource(LL_EXTI_CONFIG_PORTE, LL_EXTI_CONFIG_LINE2);

  /**/
  LL_EXTI_SetEXTISource(LL_EXTI_CONFIG_PORTE, LL_EXTI_CONFIG_LINE3);

  /**/
  EXTI_InitStruct.Line_0_31 = LL_EXTI_LINE_0;
  EXTI_InitStruct.LineCommand = ENABLE;
  EXTI_InitStruct.Mode = LL_EXTI_MODE_IT;
  EXTI_InitStruct.Trigger = LL_EXTI_TRIGGER_FALLING;
  LL_EXTI_Init(&EXTI_InitStruct);

  /**/
  EXTI_InitStruct.Line_0_31 = LL_EXTI_LINE_1;
  EXTI_InitStruct.LineCommand = ENABLE;
  EXTI_InitStruct.Mode = LL_EXTI_MODE_IT;
  EXTI_InitStruct.Trigger = LL_EXTI_TRIGGER_FALLING;
  LL_EXTI_Init(&EXTI_InitStruct);

  /**/
  EXTI_InitStruct.Line_0_31 = LL_EXTI_LINE_2;
  EXTI_InitStruct.LineCommand = ENABLE;
  EXTI_InitStruct.Mode = LL_EXTI_MODE_IT;
  EXTI_InitStruct.Trigger = LL_EXTI_TRIGGER_FALLING;
  LL_EXTI_Init(&EXTI_InitStruct);

  /**/
  EXTI_InitStruct.Line_0_31 = LL_EXTI_LINE_3;
  EXTI_InitStruct.LineCommand = ENABLE;
  EXTI_InitStruct.Mode = LL_EXTI_MODE_IT;
  EXTI_InitStruct.Trigger = LL_EXTI_TRIGGER_FALLING;
  LL_EXTI_Init(&EXTI_InitStruct);

  /**/
  LL_GPIO_SetPinPull(GPIOE, LL_GPIO_PIN_0, LL_GPIO_PULL_NO);

  /**/
  LL_GPIO_SetPinPull(GPIOE, LL_GPIO_PIN_1, LL_GPIO_PULL_NO);

  /**/
  LL_GPIO_SetPinPull(GPIOE, LL_GPIO_PIN_2, LL_GPIO_PULL_NO);

  /**/
  LL_GPIO_SetPinPull(GPIOE, LL_GPIO_PIN_3, LL_GPIO_PULL_NO);

  /**/
  LL_GPIO_SetPinMode(GPIOE, LL_GPIO_PIN_0, LL_GPIO_MODE_INPUT);

  /**/
  LL_GPIO_SetPinMode(GPIOE, LL_GPIO_PIN_1, LL_GPIO_MODE_INPUT);

  /**/
  LL_GPIO_SetPinMode(GPIOE, LL_GPIO_PIN_2, LL_GPIO_MODE_INPUT);

  /**/
  LL_GPIO_SetPinMode(GPIOE, LL_GPIO_PIN_3, LL_GPIO_MODE_INPUT);

  /* EXTI interrupt init*/
  NVIC_SetPriority(EXTI0_1_IRQn, 3);
  NVIC_EnableIRQ(EXTI0_1_IRQn);
  NVIC_SetPriority(EXTI2_3_IRQn, 3);
  NVIC_EnableIRQ(EXTI2_3_IRQn);

}

void StartDefaultTask(void *argument)
{
  for(;;)
  {
    osDelay(1);
  }
}

void HAL_TIM_PeriodElapsedCallback(TIM_HandleTypeDef *htim)
{
  if (htim->Instance == TIM6)
  {
    HAL_IncTick();
  }
}

void Error_Handler(void)
{
  __disable_irq();
  while (1)
  {
  }
}

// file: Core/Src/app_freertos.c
/* USER CODE BEGIN Header */
/**
  ******************************************************************************
  * File Name          : app_freertos.c
  * Description        : Code for freertos applications
  ******************************************************************************
  * @attention
  *
  * Copyright (c) 2026 STMicroelectronics.
  * All rights reserved.
  *
  * This software is licensed under terms that can be found in the LICENSE file
  * in the root directory of this software component.
  * If no LICENSE file comes with this software, it is provided AS-IS.
  *
  ******************************************************************************
  */
/* USER CODE END Header */

#include "FreeRTOS.h"
#include "task.h"
#include "main.h"

/* USER CODE BEGIN PREPOSTSLEEP */
__weak void PreSleepProcessing(uint32_t ulExpectedIdleTime)
{
/* place for user code */
}

__weak void PostSleepProcessing(uint32_t ulExpectedIdleTime)
{
/* place for user code */
}
/* USER CODE END PREPOSTSLEEP */
